AUTOSAR XML (schema 4-2-2)
package /ASW_COM_STD_Package
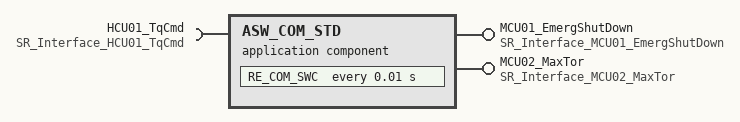
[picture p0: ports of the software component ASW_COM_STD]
  application sw component type ASW_COM_STD
    provide port MCU01_EmergShutDown: provided-interface=SR_Interface_MCU01_EmergShutDown
    provide port MCU02_MaxTor: provided-interface=SR_Interface_MCU02_MaxTor
    require port HCU01_TqCmd: nonqueued-receiver-com-spec=alive-timeout=0.3, required-interface=SR_Interface_HCU01_TqCmd
    behavior ASW_COM_STD_InternalBehavior
      timing event TE_RE_COM_SWC_10ms: start-on-event=RE_COM_SWC, period=0.01
      runnable RE_COM_SWC
        data-receive-point-by-arguments:
          access REC_HCU01_TqCmd_DE_TqCmd: accessed-variable=HCU01_TqCmd.DE_TqCmd
        data-send-points:
          access SEND_MCU01_EmergShutDown_DE_EmergShutDown: accessed-variable=MCU01_EmergShutDown.DE_EmergShutDown
          access SEND_MCU02_MaxTor_DE_MaxTor: accessed-variable=MCU02_MaxTor.DE_MaxTor
